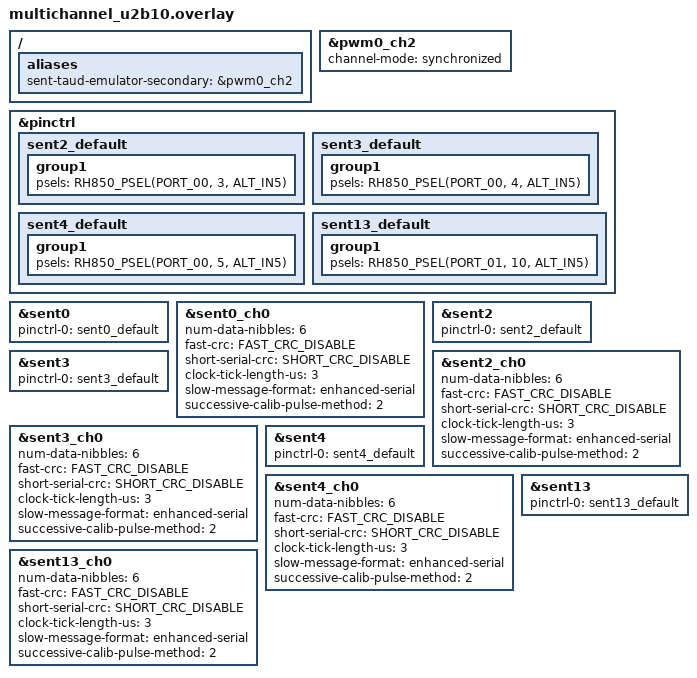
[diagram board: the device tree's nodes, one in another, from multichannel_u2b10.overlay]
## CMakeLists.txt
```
# SPDX-License-Identifier: Apache-2.0
cmake_minimum_required(VERSION 3.20.0)
find_package(Zephyr REQUIRED HINTS $ENV{ZEPHYR_BASE})
project(sent_taud_test_suite)

target_sources(app PRIVATE
  src/main.c
  src/sent_test_common.c
  src/sent_taud_emulator.c
)
target_include_directories(app PRIVATE src)
```

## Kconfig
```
# SPDX-License-Identifier: Apache-2.0

mainmenu "Renesas RH850 SENT driver tests"

source "Kconfig.zephyr"

config SENT_TAUD_TEST_CRC_MODE
	int "CRC mode: 0 disabled, 1 recommended, 2 legacy"
	range 0 2
	default 1

config SENT_TAUD_TEST_PAUSE_MODE
	int "Pause mode: 0 absent, 1 variable, 2 fixed"
	range 0 2
	default 0

config SENT_TAUD_TEST_CALIB_METHOD
	int "Successive calibration method"
	range 1 2
	default 2

config SENT_TAUD_TEST_MULTI_CHANNEL
	bool "Enable two-output multi-channel test"
	default n

config SENT_TAUD_TICK_US
	int "SENT tick length in microseconds"
	default 3
	range 1 100
	help
	  SENT tick duration used to convert raw SENT periods into
	  TAUD counter values.

config SENT_TAUD_TX_TIMEOUT_MS
	int "TAUD raw transmission timeout in milliseconds"
	default 100
	range 1 10000
	help
	  Maximum time to wait for a raw TAUD pulse sequence to finish.
```

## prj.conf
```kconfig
CONFIG_ZTEST=y
CONFIG_SENT=y

CONFIG_LOG=y
CONFIG_LOG_DEFAULT_LEVEL=3

CONFIG_SENT_RENESAS_RH850=y
CONFIG_PWM_RENESAS_RH850=n

CONFIG_MAIN_STACK_SIZE=4096
CONFIG_ISR_STACK_SIZE=4096
CONFIG_HEAP_MEM_POOL_SIZE=4096

CONFIG_ASSERT=y
CONFIG_NO_OPTIMIZATIONS=y

CONFIG_SENT_TAUD_TEST_CRC_MODE=0
CONFIG_SENT_TAUD_TEST_PAUSE_MODE=0
CONFIG_SENT_TAUD_TEST_CALIB_METHOD=2

CONFIG_SENT_TAUD_TICK_US=3
CONFIG_SENT_TAUD_TX_TIMEOUT_MS=100

CONFIG_SENT_RENESAS_RH850_SERIAL_ENHANCED_FRAME=19
```

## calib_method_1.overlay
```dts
/*
 * Copyright (c) 2026 Renesas Electronics Corporation
 * SPDX-License-Identifier: Apache-2.0
 */
&sent1_ch0 {
	successive-calib-pulse-method = <1>;
};
```

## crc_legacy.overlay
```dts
/*
 * Copyright (c) 2026 Renesas Electronics Corporation
 * SPDX-License-Identifier: Apache-2.0
 */
&sent1_ch0 {
	fast-crc = <FAST_CRC_LEGACY_IMPLEMENTATION>;
	short-serial-crc = <SHORT_CRC_LEGACY_IMPLEMENTATION>;
};
```

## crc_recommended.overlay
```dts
/*
 * Copyright (c) 2026 Renesas Electronics Corporation
 * SPDX-License-Identifier: Apache-2.0
 */
&sent1_ch0 {
	fast-crc = <FAST_CRC_RECOMMENDED_IMPLEMENTATION>;
	short-serial-crc = <SHORT_CRC_RECOMMENDED_IMPLEMENTATION>;
};
```

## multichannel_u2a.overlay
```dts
/*
 * Copyright (c) 2026 Renesas Electronics Corporation
 * SPDX-License-Identifier: Apache-2.0
 */

#include <zephyr/dt-bindings/sent/sent.h>

/ {
	aliases {
		sent-taud-emulator-secondary = &pwm0_ch2;
	};
};

/*
 * Enable TAUD0 channel 2 as the second synchronized PWM output.
 * The master channel and primary slave are enabled by the board overlay.
 */
&pwm0_ch2 {
	channel-mode = "synchronized";
	status = "okay";
};

/*
 * Keep these pin configurations test-local instead of exposing them as
 * default board pinctrl nodes.
 */
&pinctrl {
	sent2_default: sent2_default {
		group1 {
			psels = <RH850_PSEL(PORT_04, 13, ALT_IN2)>;
		};
	};

	sent3_default: sent3_default {
		group1 {
			psels = <RH850_PSEL(PORT_04, 12, ALT_IN4)>;
		};
	};

	sent4_default: sent4_default {
		group1 {
			psels = <RH850_PSEL(PORT_06, 13, ALT_IN3)>;
		};
	};
};

/* SENT1 is already enabled by the board overlay. */
&sent0 {
	pinctrl-0 = <&sent0_default>;
	pinctrl-names = "default";
	status = "okay";
};

&sent0_ch0 {
	num-data-nibbles = <6>;
	fast-crc = <FAST_CRC_DISABLE>;
	short-serial-crc = <SHORT_CRC_DISABLE>;
	clock-tick-length-us = <3>;
	slow-message-format = "enhanced-serial";
	successive-calib-pulse-method = <2>;
	status = "okay";
};

&sent2 {
	pinctrl-0 = <&sent2_default>;
	pinctrl-names = "default";
	status = "okay";
};

&sent2_ch0 {
	num-data-nibbles = <6>;
	fast-crc = <FAST_CRC_DISABLE>;
	short-serial-crc = <SHORT_CRC_DISABLE>;
	clock-tick-length-us = <3>;
	slow-message-format = "enhanced-serial";
	successive-calib-pulse-method = <2>;
	status = "okay";
};

&sent3 {
	pinctrl-0 = <&sent3_default>;
	pinctrl-names = "default";
	status = "okay";
};

&sent3_ch0 {
	num-data-nibbles = <6>;
	fast-crc = <FAST_CRC_DISABLE>;
	short-serial-crc = <SHORT_CRC_DISABLE>;
	clock-tick-length-us = <3>;
	slow-message-format = "enhanced-serial";
	successive-calib-pulse-method = <2>;
	status = "okay";
};

&sent4 {
	pinctrl-0 = <&sent4_default>;
	pinctrl-names = "default";
	status = "okay";
};

&sent4_ch0 {
	num-data-nibbles = <6>;
	fast-crc = <FAST_CRC_DISABLE>;
	short-serial-crc = <SHORT_CRC_DISABLE>;
	clock-tick-length-us = <3>;
	slow-message-format = "enhanced-serial";
	successive-calib-pulse-method = <2>;
	status = "okay";
};

#undef SENT_CHANNEL_CONFIG
```

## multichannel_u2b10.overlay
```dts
/*
 * Copyright (c) 2026 Renesas Electronics Corporation
 * SPDX-License-Identifier: Apache-2.0
 *
 * U2B10 multi-channel SENT test overlay.
 *
 * SENT13 is U2B10-specific and is included in main.c only when node label
 * sent13 exists and has status = "okay".
 */

#include <zephyr/dt-bindings/sent/sent.h>

/ {
	aliases {
		sent-taud-emulator-secondary = &pwm0_ch2;
	};
};

/*
 * Enable TAUD0 channel 2 as the second synchronized PWM output.
 * The master channel and primary slave are enabled by the board overlay.
 */
&pwm0_ch2 {
	channel-mode = "synchronized";
	status = "okay";
};

&pinctrl {
	sent2_default: sent2_default {
		group1 {
			psels = <RH850_PSEL(PORT_00, 3, ALT_IN5)>;
		};
	};

	sent3_default: sent3_default {
		group1 {
			psels = <RH850_PSEL(PORT_00, 4, ALT_IN5)>;
		};
	};

	sent4_default: sent4_default {
		group1 {
			psels = <RH850_PSEL(PORT_00, 5, ALT_IN5)>;
		};
	};

	sent13_default: sent13_default {
		group1 {
			psels = <RH850_PSEL(PORT_01, 10, ALT_IN5)>;
		};
	};
};

/* SENT1 is already enabled by the board overlay. */
&sent0 {
	pinctrl-0 = <&sent0_default>;
	pinctrl-names = "default";
	status = "okay";
};

&sent0_ch0 {
	num-data-nibbles = <6>;
	fast-crc = <FAST_CRC_DISABLE>;
	short-serial-crc = <SHORT_CRC_DISABLE>;
	clock-tick-length-us = <3>;
	slow-message-format = "enhanced-serial";
	successive-calib-pulse-method = <2>;
	status = "okay";
};

&sent2 {
	pinctrl-0 = <&sent2_default>;
	pinctrl-names = "default";
	status = "okay";
};

&sent2_ch0 {
	num-data-nibbles = <6>;
	fast-crc = <FAST_CRC_DISABLE>;
	short-serial-crc = <SHORT_CRC_DISABLE>;
	clock-tick-length-us = <3>;
	slow-message-format = "enhanced-serial";
	successive-calib-pulse-method = <2>;
	status = "okay";
};

&sent3 {
	pinctrl-0 = <&sent3_default>;
	pinctrl-names = "default";
	status = "okay";
};

&sent3_ch0 {
	num-data-nibbles = <6>;
	fast-crc = <FAST_CRC_DISABLE>;
	short-serial-crc = <SHORT_CRC_DISABLE>;
	clock-tick-length-us = <3>;
	slow-message-format = "enhanced-serial";
	successive-calib-pulse-method = <2>;
	status = "okay";
};

&sent4 {
	pinctrl-0 = <&sent4_default>;
	pinctrl-names = "default";
	status = "okay";
};

&sent4_ch0 {
	num-data-nibbles = <6>;
	fast-crc = <FAST_CRC_DISABLE>;
	short-serial-crc = <SHORT_CRC_DISABLE>;
	clock-tick-length-us = <3>;
	slow-message-format = "enhanced-serial";
	successive-calib-pulse-method = <2>;
	status = "okay";
};

&sent13 {
	pinctrl-0 = <&sent13_default>;
	pinctrl-names = "default";
	status = "okay";
};

&sent13_ch0 {
	num-data-nibbles = <6>;
	fast-crc = <FAST_CRC_DISABLE>;
	short-serial-crc = <SHORT_CRC_DISABLE>;
	clock-tick-length-us = <3>;
	slow-message-format = "enhanced-serial";
	successive-calib-pulse-method = <2>;
	status = "okay";
};

#undef SENT_CHANNEL_CONFIG
```

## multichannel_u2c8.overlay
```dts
/*
 * Copyright (c) 2026 Renesas Electronics Corporation
 * SPDX-License-Identifier: Apache-2.0
 */

#include <zephyr/dt-bindings/sent/sent.h>

/ {
	aliases {
		sent-taud-emulator-secondary = &pwm0_ch2;
	};
};

/*
 * Enable TAUD0 channel 2 as the second synchronized PWM output.
 * The master channel and primary slave are enabled by the board overlay.
 */
&pwm0_ch2 {
	channel-mode = "synchronized";
	status = "okay";
};

&pinctrl {
	sent2_default: sent2_default {
		group1 {
			psels = <RH850_PSEL(PORT_02, 9, ALT_IN5)>;
		};
	};

	sent3_default: sent3_default {
		group1 {
			psels = <RH850_PSEL(PORT_04, 13, ALT_IN5)>;
		};
	};

	sent4_default: sent4_default {
		group1 {
			psels = <RH850_PSEL(PORT_04, 15, ALT_IN6)>;
		};
	};
};

/* SENT1 is already enabled by the board overlay. */
&sent0 {
	pinctrl-0 = <&sent0_default>;
	pinctrl-names = "default";
	status = "okay";
};

&sent0_ch0 {
	num-data-nibbles = <6>;
	fast-crc = <FAST_CRC_DISABLE>;
	short-serial-crc = <SHORT_CRC_DISABLE>;
	clock-tick-length-us = <3>;
	slow-message-format = "enhanced-serial";
	successive-calib-pulse-method = <2>;
	status = "okay";
};

&sent2 {
	pinctrl-0 = <&sent2_default>;
	pinctrl-names = "default";
	status = "okay";
};

&sent2_ch0 {
	num-data-nibbles = <6>;
	fast-crc = <FAST_CRC_DISABLE>;
	short-serial-crc = <SHORT_CRC_DISABLE>;
	clock-tick-length-us = <3>;
	slow-message-format = "enhanced-serial";
	successive-calib-pulse-method = <2>;
	status = "okay";
};

&sent3 {
	pinctrl-0 = <&sent3_default>;
	pinctrl-names = "default";
	status = "okay";
};

&sent3_ch0 {
	num-data-nibbles = <6>;
	fast-crc = <FAST_CRC_DISABLE>;
	short-serial-crc = <SHORT_CRC_DISABLE>;
	clock-tick-length-us = <3>;
	slow-message-format = "enhanced-serial";
	successive-calib-pulse-method = <2>;
	status = "okay";
};

&sent4 {
	pinctrl-0 = <&sent4_default>;
	pinctrl-names = "default";
	status = "okay";
};

&sent4_ch0 {
	num-data-nibbles = <6>;
	fast-crc = <FAST_CRC_DISABLE>;
	short-serial-crc = <SHORT_CRC_DISABLE>;
	clock-tick-length-us = <3>;
	slow-message-format = "enhanced-serial";
	successive-calib-pulse-method = <2>;
	status = "okay";
};


#undef SENT_CHANNEL_CONFIG
```

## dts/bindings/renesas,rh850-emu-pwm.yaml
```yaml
# Copyright (c) 2026 Renesas Electronics Corporation
# SPDX-License-Identifier: Apache-2.0

description: |
  Renesas RH850 TAUD-Emulator PWM driver (master/slave).

  Used for both master and slave nodes:
  - Master node: channel-type = "master" (timing source, no PWM output)
  - Slave node:  channel-type = "slave"  (PWM output, requires a Master Channel phandle)

compatible: "renesas,rh850-emu-pwm"

include: [base.yaml, pinctrl-device.yaml]

properties:
  reg:
    required: true

  unit:
    type: int
    required: true
    description: |
      TAUD Unit number (e.g. 0 for TAUD0).
      The valid range depends on the available hardware.

  channel:
    type: int
    required: true
    description: TAUD Channel number within the Unit (range from 0 to 15).

  channel-type:
    type: string
    required: true
    enum:
      - "master"
      - "slave"
    description: |
      Type of TAUD channel:

      "master" - Timing source used to set the PWM period/frequency.
                 It does not output the PWM signal directly.

      "slave"  - PWM output channel used to set the duty cycle.
                 It must reference a Master Channel by phandle.

  master:
    type: phandle
    description: Phandle to the master TAUD channel node.
      Required for slave nodes (channel-type = "slave").
      Must not be present for master nodes.

  interrupts:
    required: true

  "#pwm-cells":
    type: int
    const: 3

pwm-cells:
  - channel
  - period
  - flags
```

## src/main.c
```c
/*
 * Copyright (c) 2026 Renesas Electronics Corporation
 * SPDX-License-Identifier: Apache-2.0
 */

#include <stdbool.h>
#include <stddef.h>
#include <stdint.h>

#include <zephyr/device.h>
#include <zephyr/devicetree.h>
#include <zephyr/kernel.h>
#include <zephyr/sys/util.h>
#include <zephyr/ztest.h>

#include "sent_taud_emulator.h"
#include "sent_test_common.h"
#include "sent_test_vectors.h"

#define SENT0_NODE DT_ALIAS(sent0)

#if !DT_NODE_EXISTS(SENT0_NODE)
#error "sent0 Devicetree alias is not defined"
#endif

#if !DT_NODE_HAS_STATUS_OKAY(SENT0_NODE)
#error "sent0 Devicetree node is not enabled"
#endif

#define TEST_RX_TIMEOUT K_MSEC(250U)

static const struct device *const sent0 = DEVICE_DT_GET(SENT0_NODE);
static struct sent_test_rx_context rx0;
static bool sent0_started;

#if IS_ENABLED(CONFIG_SENT_TAUD_TEST_MULTI_CHANNEL)

/*
 * The multichannel overlay enables all required physical RSENT instances.
 * Do not use aliases here because the base overlay may map alias sent0 to a
 * different physical node for the normal single-channel tests.
 */
#define SENT_PHYS0_NODE  DT_NODELABEL(sent0)
#define SENT_PHYS1_NODE  DT_NODELABEL(sent1)
#define SENT_PHYS2_NODE  DT_NODELABEL(sent2)
#define SENT_PHYS3_NODE  DT_NODELABEL(sent3)
#define SENT_PHYS4_NODE  DT_NODELABEL(sent4)
#define SENT_PHYS13_NODE DT_NODELABEL(sent13)

#if DT_NODE_EXISTS(SENT_PHYS13_NODE) && DT_NODE_HAS_STATUS_OKAY(SENT_PHYS13_NODE)
#define MULTI_HAS_SENT13 1
#else
#define MULTI_HAS_SENT13 0
#endif

BUILD_ASSERT(DT_NODE_HAS_STATUS_OKAY(SENT_PHYS0_NODE),
			 "multichannel requires physical SENT0");
BUILD_ASSERT(DT_NODE_HAS_STATUS_OKAY(SENT_PHYS1_NODE),
			 "multichannel requires physical SENT1");
BUILD_ASSERT(DT_NODE_HAS_STATUS_OKAY(SENT_PHYS2_NODE),
			 "multichannel requires physical SENT2");
BUILD_ASSERT(DT_NODE_HAS_STATUS_OKAY(SENT_PHYS3_NODE),
			 "multichannel requires physical SENT3");
BUILD_ASSERT(DT_NODE_HAS_STATUS_OKAY(SENT_PHYS4_NODE),
			 "multichannel requires physical SENT4");

#if MULTI_HAS_SENT13
BUILD_ASSERT(DT_NODE_HAS_STATUS_OKAY(SENT_PHYS13_NODE),
			 "multichannel SENT13 node must be enabled");
#define MULTI_SENT_COUNT 6U
#else
#define MULTI_SENT_COUNT 5U
#endif

static const struct device *const multi_sent_devs[MULTI_SENT_COUNT] = {
	DEVICE_DT_GET(SENT_PHYS0_NODE),
	DEVICE_DT_GET(SENT_PHYS1_NODE),
	DEVICE_DT_GET(SENT_PHYS2_NODE),
	DEVICE_DT_GET(SENT_PHYS3_NODE),
	DEVICE_DT_GET(SENT_PHYS4_NODE),
#if MULTI_HAS_SENT13
	DEVICE_DT_GET(SENT_PHYS13_NODE),
#endif
};

static struct sent_test_rx_context multi_rx[MULTI_SENT_COUNT];
static bool multi_started[MULTI_SENT_COUNT];

static uint32_t multi_sent_hw_channel(size_t index)
{
	static const uint32_t hw_channels[] = {
		0U, 1U, 2U, 3U, 4U,
#if MULTI_HAS_SENT13
		13U,
#endif
	};

	return hw_channels[index];
}

#endif /* CONFIG_SENT_TAUD_TEST_MULTI_CHANNEL */

static void send_raw(const uint32_t *periods, size_t period_count)
{
	int ret = sent_taud_emulator_send_raw(periods, period_count);

	zassert_equal(ret, 0, "TAUD raw transmission failed: %d", ret);
}

static void start_fast(uint32_t frame_count)
{
	int ret = sent_test_start_fast(sent0, &rx0, frame_count);

	zassert_equal(ret, 0, "Failed to start Fast Channel reception: %d", ret);
	sent0_started = true;
}

static void wait_fast(void)
{
	int ret = k_sem_take(&rx0.done, TEST_RX_TIMEOUT);

	zassert_equal(ret, 0, "Timed out waiting for Fast Channel callback");
}

static void assert_zero_data_frame(const struct sent_frame *frame)
{
	zassert_equal(frame->type, SENT_FAST_FRAME);
	zassert_equal(frame->fast.data_nibbles[0], 0U);
	zassert_equal(frame->fast.data_nibbles[1], 0U);
	zassert_equal(frame->fast.data_nibbles[2], 0U);
	zassert_equal(frame->fast.data_nibbles[3], 0U);
	zassert_equal(frame->fast.data_nibbles[4], 0U);
	zassert_equal(frame->fast.data_nibbles[5], 0U);
}

static void assert_crc_payload_frame(const struct sent_frame *frame)
{
	zassert_equal(frame->type, SENT_FAST_FRAME);
	zassert_equal(frame->fast.data_nibbles[0], 0x1U);
	zassert_equal(frame->fast.data_nibbles[1], 0x2U);
	zassert_equal(frame->fast.data_nibbles[2], 0x3U);
	zassert_equal(frame->fast.data_nibbles[3], 0x4U);
	zassert_equal(frame->fast.data_nibbles[4], 0x5U);
	zassert_equal(frame->fast.data_nibbles[5], 0x6U);
}

static void *suite_setup(void)
{
	int ret;

	zassert_true(device_is_ready(sent0), "sent0 is not ready");

	ret = sent_test_rx_context_init(&rx0);
	zassert_equal(ret, 0, "Failed to initialize RX context: %d", ret);

#if IS_ENABLED(CONFIG_SENT_TAUD_TEST_MULTI_CHANNEL)
	for (size_t i = 0U; i < MULTI_SENT_COUNT; i++) {
		zassert_true(device_is_ready(multi_sent_devs[i]),
					 "Physical SENT%u is not ready", multi_sent_hw_channel(i));

		ret = sent_test_rx_context_init(&multi_rx[i]);
		zassert_equal(ret, 0,
					  "Failed to initialize physical SENT%u RX context: %d",
					  multi_sent_hw_channel(i), ret);
	}
#endif

	ret = sent_taud_emulator_open();
	zassert_equal(ret, 0, "Failed to open TAUD emulator: %d", ret);

	return NULL;
}

static void before(void *fixture)
{
	ARG_UNUSED(fixture);

	sent0_started = false;
	sent_test_rx_context_reset(&rx0);

#if IS_ENABLED(CONFIG_SENT_TAUD_TEST_MULTI_CHANNEL)
	for (size_t i = 0U; i < MULTI_SENT_COUNT; i++) {
		multi_started[i] = false;
		sent_test_rx_context_reset(&multi_rx[i]);
	}
#endif
}

static void after(void *fixture)
{
	int ret;

	ARG_UNUSED(fixture);

	if (sent0_started) {
		ret = sent_test_stop(sent0);
		zassert_equal(ret, 0, "Failed to stop SENT receiver: %d", ret);
		sent0_started = false;
	}

#if IS_ENABLED(CONFIG_SENT_TAUD_TEST_MULTI_CHANNEL)
	for (size_t i = 0U; i < MULTI_SENT_COUNT; i++) {
		if (!multi_started[i]) {
			continue;
		}

		ret = sent_test_stop(multi_sent_devs[i]);
		zassert_equal(ret, 0, "Failed to stop physical SENT%u: %d",
					  multi_sent_hw_channel(i), ret);
		multi_started[i] = false;
	}
#endif
}

static void suite_teardown(void *fixture)
{
	int ret;

	ARG_UNUSED(fixture);

	ret = sent_taud_emulator_close();
	zassert_equal(ret, 0, "Failed to close TAUD emulator: %d", ret);
}

ZTEST(sent_rh850_taud_raw, test_reference_vector_19_frames)
{
#if IS_ENABLED(CONFIG_SENT_TAUD_TEST_MULTI_CHANNEL) || \
	(CONFIG_SENT_TAUD_TEST_PAUSE_MODE != 0) || \
	(CONFIG_SENT_TAUD_TEST_CRC_MODE != 0)
	ztest_test_skip();
#else
	start_fast(FSP_REFERENCE_FRAME_COUNT);
	send_raw(fsp_enhanced_serial_format_0_pulses,
			 ARRAY_SIZE(fsp_enhanced_serial_format_0_pulses));
	wait_fast();

	zassert_equal(rx0.callback_count, 1U);
	zassert_equal(rx0.frame_total, FSP_REFERENCE_FRAME_COUNT);
	assert_zero_data_frame(&rx0.frames[0]);
	zassert_equal(rx0.frames[2].fast.data_nibbles[5], 0x1U);
	zassert_equal(rx0.frames[18].fast.data_nibbles[4], 0x1U);
	zassert_equal(rx0.frames[18].fast.data_nibbles[5], 0x1U);
#endif
}

ZTEST(sent_rh850_taud_raw, test_known_good_single_frame)
{
#if IS_ENABLED(CONFIG_SENT_TAUD_TEST_MULTI_CHANNEL) || \
	(CONFIG_SENT_TAUD_TEST_PAUSE_MODE != 0) || \
	(CONFIG_SENT_TAUD_TEST_CRC_MODE != 0)
	ztest_test_skip();
#else
	start_fast(1U);
	send_raw(known_good_single_frame, ARRAY_SIZE(known_good_single_frame));
	wait_fast();

	zassert_equal(rx0.callback_count, 1U);
	zassert_equal(rx0.frame_total, 1U);
	assert_zero_data_frame(&rx0.frames[0]);
#endif
}

ZTEST(sent_rh850_taud_raw, test_calibration_error_recovery)
{
#if IS_ENABLED(CONFIG_SENT_TAUD_TEST_MULTI_CHANNEL) || \
	(CONFIG_SENT_TAUD_TEST_PAUSE_MODE != 0) || \
	(CONFIG_SENT_TAUD_TEST_CRC_MODE != 0)
	ztest_test_skip();
#else
	start_fast(1U);
	send_raw(bad_calibration_single_frame,
			 ARRAY_SIZE(bad_calibration_single_frame));
	k_msleep(20U);
	zassert_equal(rx0.callback_count, 0U,
				  "Invalid calibration unexpectedly produced a Fast callback");

	send_raw(known_good_single_frame, ARRAY_SIZE(known_good_single_frame));
	wait_fast();
	zassert_equal(rx0.callback_count, 1U);
	zassert_equal(rx0.frame_total, 1U);
	assert_zero_data_frame(&rx0.frames[0]);
#endif
}

ZTEST(sent_rh850_taud_raw, test_crc_valid_raw)
{
#if IS_ENABLED(CONFIG_SENT_TAUD_TEST_MULTI_CHANNEL) || \
	(CONFIG_SENT_TAUD_TEST_PAUSE_MODE != 0)
	ztest_test_skip();
#elif CONFIG_SENT_TAUD_TEST_CRC_MODE == 1
	start_fast(1U);
	send_raw(recommended_crc_single_frame,
			 ARRAY_SIZE(recommended_crc_single_frame));
	wait_fast();
	zassert_equal(rx0.callback_count, 1U);
	zassert_equal(rx0.frame_total, 1U);
	assert_crc_payload_frame(&rx0.frames[0]);
#elif CONFIG_SENT_TAUD_TEST_CRC_MODE == 2
	start_fast(1U);
	send_raw(legacy_crc_single_frame, ARRAY_SIZE(legacy_crc_single_frame));
	wait_fast();
	zassert_equal(rx0.callback_count, 1U);
	zassert_equal(rx0.frame_total, 1U);
	assert_crc_payload_frame(&rx0.frames[0]);
#else
	ztest_test_skip();
#endif
}

ZTEST(sent_rh850_taud_raw, test_crc_error_recovery_raw)
{
#if IS_ENABLED(CONFIG_SENT_TAUD_TEST_MULTI_CHANNEL) || \
	(CONFIG_SENT_TAUD_TEST_PAUSE_MODE != 0) || \
	(CONFIG_SENT_TAUD_TEST_CRC_MODE == 0)
	ztest_test_skip();
#elif CONFIG_SENT_TAUD_TEST_CRC_MODE == 1
	start_fast(1U);
	send_raw(bad_recommended_crc_single_frame,
			 ARRAY_SIZE(bad_recommended_crc_single_frame));
	k_msleep(20U);
	zassert_equal(rx0.callback_count, 0U);

	send_raw(recommended_crc_single_frame,
			 ARRAY_SIZE(recommended_crc_single_frame));
	wait_fast();
	zassert_equal(rx0.callback_count, 1U);
	zassert_equal(rx0.frame_total, 1U);
	assert_crc_payload_frame(&rx0.frames[0]);
#else
	start_fast(1U);
	send_raw(bad_legacy_crc_single_frame,
			 ARRAY_SIZE(bad_legacy_crc_single_frame));
	k_msleep(20U);
	zassert_equal(rx0.callback_count, 0U);

	send_raw(legacy_crc_single_frame, ARRAY_SIZE(legacy_crc_single_frame));
	wait_fast();
	zassert_equal(rx0.callback_count, 1U);
	zassert_equal(rx0.frame_total, 1U);
	assert_crc_payload_frame(&rx0.frames[0]);
#endif
}

ZTEST(sent_rh850_taud_raw, test_pause_pulse_raw)
{
#if IS_ENABLED(CONFIG_SENT_TAUD_TEST_MULTI_CHANNEL) || \
	(CONFIG_SENT_TAUD_TEST_PAUSE_MODE == 0)
	ztest_test_skip();
#elif CONFIG_SENT_TAUD_TEST_PAUSE_MODE == 1
	start_fast(4U);
	send_raw(variable_pause_frames, ARRAY_SIZE(variable_pause_frames));
	wait_fast();

	zassert_equal(rx0.callback_count, 1U);
	zassert_equal(rx0.frame_total, 4U);
	assert_zero_data_frame(&rx0.frames[0]);
	assert_zero_data_frame(&rx0.frames[1]);
	assert_zero_data_frame(&rx0.frames[2]);
	assert_zero_data_frame(&rx0.frames[3]);
#else
	start_fast(4U);
	send_raw(fixed_pause_frames, ARRAY_SIZE(fixed_pause_frames));
	wait_fast();

	zassert_equal(rx0.callback_count, 1U);
	zassert_equal(rx0.frame_total, 4U);
	assert_zero_data_frame(&rx0.frames[0]);
	assert_zero_data_frame(&rx0.frames[1]);
	assert_zero_data_frame(&rx0.frames[2]);
	assert_zero_data_frame(&rx0.frames[3]);
#endif
}

/*
 * Keep this ZTEST visible in every configuration so Twister receives an
 * explicit SKIP instead of retaining a None status in non-multichannel runs.
 */
ZTEST(sent_rh850_taud_raw, test_multichannel_same_stream_all_receivers)
{
#if !IS_ENABLED(CONFIG_SENT_TAUD_TEST_MULTI_CHANNEL)
	ztest_test_skip();
#else
	int ret;

	/*
	 * Arm every physical receiver first. sent_test_start_fast() registers
	 * sent_test_fast_cb() with &multi_rx[i] as user_data and starts listening.
	 */
	for (size_t i = 0U; i < MULTI_SENT_COUNT; i++) {
		ret = sent_test_start_fast(multi_sent_devs[i], &multi_rx[i],
								   FSP_REFERENCE_FRAME_COUNT);
		zassert_equal(ret, 0,
					  "Failed to start physical SENT%u: %d",
					  multi_sent_hw_channel(i), ret);
		multi_started[i] = true;
	}

	/* One TAUD transmission is observed by every wired physical receiver. */
	send_raw(fsp_enhanced_serial_format_0_pulses,
			 ARRAY_SIZE(fsp_enhanced_serial_format_0_pulses));

	/* The callback gives multi_rx[i].done through its user_data context. */
	for (size_t i = 0U; i < MULTI_SENT_COUNT; i++) {
		ret = k_sem_take(&multi_rx[i].done, TEST_RX_TIMEOUT);

		if (ret != 0) {
			printk("SENT timeout: index=%u physical=%u ret=%d "
				   "callback_count=%u frame_total=%u\n",
				   (unsigned int)i,
				   multi_sent_hw_channel(i),
				   ret,
				   multi_rx[i].callback_count,
				   multi_rx[i].frame_total);
		}

		zassert_equal(ret, 0,
					  "Timed out waiting for physical SENT%u callback: ret=%d",
					  multi_sent_hw_channel(i), ret);
	}

	for (size_t i = 0U; i < MULTI_SENT_COUNT; i++) {
		zassert_equal(multi_rx[i].callback_count, 1U,
				"Unexpected physical SENT%u callback count: %u",
				multi_sent_hw_channel(i),
				multi_rx[i].callback_count);

		zassert_equal(multi_rx[i].frame_total,
				FSP_REFERENCE_FRAME_COUNT,
				"Unexpected physical SENT%u frame total: %u",
				multi_sent_hw_channel(i),
				multi_rx[i].frame_total);

		assert_zero_data_frame(&multi_rx[i].frames[0]);

		TC_PRINT("SENT%u:\n", multi_sent_hw_channel(i));

		for (size_t frame = 0U; frame < FSP_REFERENCE_FRAME_COUNT; frame++) {
			const struct sent_frame *f = &multi_rx[i].frames[frame];

			TC_PRINT(
				"frame %02u: %X %X %X %X %X %X "
				"(exp4=%X exp5=%X)\n",
				frame,
				f->fast.data_nibbles[0],
				f->fast.data_nibbles[1],
				f->fast.data_nibbles[2],
				f->fast.data_nibbles[3],
				f->fast.data_nibbles[4],
				f->fast.data_nibbles[5],
				expected_nibble4[frame],
				expected_final_nibble[frame]);

			zassert_equal(
				f->fast.data_nibbles[4],
				expected_nibble4[frame],
				"Physical SENT%u frame %u nibble4 mismatch",
				multi_sent_hw_channel(i),
				frame);

			zassert_equal(
				f->fast.data_nibbles[5],
				expected_final_nibble[frame],
				"Physical SENT%u frame %u nibble5 mismatch",
				multi_sent_hw_channel(i),
				frame);
		}
	}
#endif
}

ZTEST_SUITE(sent_rh850_taud_raw,
			NULL,
			suite_setup,
			before,
			after,
			suite_teardown);
```

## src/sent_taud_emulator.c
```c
/*
 * Copyright (c) 2026 Renesas Electronics Corporation
 * SPDX-License-Identifier: Apache-2.0
 */
#include "sent_taud_emulator.h"

#include <errno.h>
#include <stdbool.h>
#include <stddef.h>
#include <stdint.h>

#include <zephyr/devicetree.h>
#include <zephyr/drivers/clock_control.h>
#include <zephyr/drivers/pinctrl.h>
#include <zephyr/irq.h>
#include <zephyr/kernel.h>
#include <zephyr/logging/log.h>
#include <zephyr/sys/util.h>

#include "bsp_api.h"

LOG_MODULE_REGISTER(
	sent_taud_emulator,
	CONFIG_LOG_DEFAULT_LEVEL);

/*
 * The sent-taud-emulator alias points directly to the TAUD slave
 * channel used as the SENT output.
 *
 * Example:
 *
 * / {
 *     aliases {
 *         sent-taud-emulator = &pwm0_slave;
 *     };
 * };
 */
#define SENT_TAUD_EMULATOR_NODE \
	DT_ALIAS(sent_taud_emulator)

#if !DT_NODE_EXISTS(SENT_TAUD_EMULATOR_NODE)
#error "sent-taud-emulator Devicetree alias is not defined"
#endif

#if !DT_NODE_HAS_STATUS_OKAY(SENT_TAUD_EMULATOR_NODE)
#error "SENT TAUD emulator Devicetree node is not enabled"
#endif

/*
 * Optional second slave output.
 *
 * When sent-taud-emulator-secondary is present and enabled, both slaves
 * follow the same master period stream. Only the primary slave interrupt
 * advances active_pulse_index; the secondary slave is output-only.
 */
#define SENT_TAUD_EMULATOR_SECONDARY_NODE \
	DT_ALIAS(sent_taud_emulator_secondary)

#if DT_NODE_EXISTS(SENT_TAUD_EMULATOR_SECONDARY_NODE) && \
	DT_NODE_HAS_STATUS_OKAY(SENT_TAUD_EMULATOR_SECONDARY_NODE)
#define EMU_HAS_SECONDARY_SLAVE 1
#else
#define EMU_HAS_SECONDARY_SLAVE 0
#endif

/*
 * The alias points to a synchronized output child of the standard TAUD PWM
 * binding. Its parent is the primary TAUD channel used as the master.
 */
#define EMU_MASTER_NODE \
	DT_PARENT(SENT_TAUD_EMULATOR_NODE)

#if !DT_NODE_HAS_STATUS_OKAY(EMU_MASTER_NODE)
#error "SENT TAUD emulator primary channel is not enabled"
#endif

#if EMU_HAS_SECONDARY_SLAVE
#define EMU_SECONDARY_MASTER_NODE \
	DT_PARENT(SENT_TAUD_EMULATOR_SECONDARY_NODE)
#endif

/*
 * TAUD instance and channel configuration.
 */
#define EMU_TAUD_UNIT \
	DT_PROP(EMU_MASTER_NODE, unit)

#define EMU_MASTER_CH \
	DT_PROP(EMU_MASTER_NODE, channel)

#define EMU_SLAVE_CH \
	DT_REG_ADDR(SENT_TAUD_EMULATOR_NODE)

#if EMU_HAS_SECONDARY_SLAVE
#define EMU_SECONDARY_SLAVE_CH \
	DT_REG_ADDR(SENT_TAUD_EMULATOR_SECONDARY_NODE)
#endif

/*
 * All synchronized children use the clock owned by the primary node.
 */
#define EMU_CLOCK_CTLR \
	DT_CLOCKS_CTLR(EMU_MASTER_NODE)

#define EMU_CLOCK_ID \
	DT_CLOCKS_CELL(EMU_MASTER_NODE, clk_id)

static const struct device *const emulator_clock_dev =
	DEVICE_DT_GET(EMU_CLOCK_CTLR);

/*
 * TAUD interrupt configuration.
 */
#define EMU_MASTER_IRQ \
	DT_IRQN(EMU_MASTER_NODE)

#define EMU_SLAVE_IRQ \
	DT_IRQN(SENT_TAUD_EMULATOR_NODE)

#define EMU_MASTER_IRQ_PRIORITY \
	DT_IRQ(EMU_MASTER_NODE, priority)

#define EMU_SLAVE_IRQ_PRIORITY \
	DT_IRQ(SENT_TAUD_EMULATOR_NODE, priority)

BUILD_ASSERT(
	EMU_TAUD_UNIT == 0U,
	"Current SENT emulator supports TAUD0 only");

BUILD_ASSERT(
	EMU_MASTER_CH == 0U,
	"Current SENT emulator expects TAUD0 channel 0 as primary");

#if EMU_HAS_SECONDARY_SLAVE
BUILD_ASSERT(
	DT_SAME_NODE(EMU_MASTER_NODE, EMU_SECONDARY_MASTER_NODE),
	"Primary and secondary slaves must use the same TAUD master");
BUILD_ASSERT(
	EMU_SLAVE_CH != EMU_SECONDARY_SLAVE_CH,
	"Primary and secondary TAUD slave channels must differ");
#define EMU_SECONDARY_CH_MASK BIT(EMU_SECONDARY_SLAVE_CH)
#else
#define EMU_SECONDARY_CH_MASK 0U
#endif

#define EMU_CH_MASK \
	(BIT(EMU_MASTER_CH) | BIT(EMU_SLAVE_CH) | EMU_SECONDARY_CH_MASK)

/*
 * The standard binding routes all synchronized output pins through the
 * primary TAUD node.
 */
PINCTRL_DT_DEFINE(EMU_MASTER_NODE);

static const struct pinctrl_dev_config *const emulator_pinctrl =
	PINCTRL_DT_DEV_CONFIG_GET(
		EMU_MASTER_NODE);

/*
 * The current TAUD configuration produces a 10 MHz counter clock.
 *
 * Therefore:
 *
 *     1 us = 10 TAUD counts
 */
#define EMU_COUNTS_PER_US 10U

/*
 * Fixed low-level pulse width used by the TAUD slave output channel.
 *
 * This matches the original FSP test emulator:
 *
 *     slave CDR = 5 SENT ticks
 */
#define EMU_LOW_TICKS 5U

K_SEM_DEFINE(tx_done, 0, 1);

/*
 * Active raw pulse stream.
 *
 * The caller must keep the source array valid until
 * sent_taud_emulator_send_raw() returns.
 */
static const uint32_t *active_pulses;
static size_t active_pulse_count;
static volatile size_t active_pulse_index;
static bool emulator_opened;

/*
 * Debug information retained after a timeout.
 *
 * These variables can be inspected directly from the debugger.
 */
volatile size_t sent_taud_debug_pulse_index;
volatile size_t sent_taud_debug_pulse_count;
volatile uint32_t sent_taud_debug_current_ticks;

/*
 * Convert a raw SENT tick count into the value expected by TAUDnCDR.
 *
 * TAUD counts from the configured value down to zero, therefore the
 * programmed value is:
 *
 *     number_of_counts - 1
 */
static uint16_t sent_taud_ticks_to_counter(uint32_t ticks)
{
	uint64_t counter_value;

	__ASSERT_NO_MSG(ticks > 0U);

	counter_value =
		(uint64_t)ticks *
		(uint64_t)CONFIG_SENT_TAUD_TICK_US *
		(uint64_t)EMU_COUNTS_PER_US;

	__ASSERT_NO_MSG(
		counter_value <=
		((uint64_t)UINT16_MAX + 1U));

	return (uint16_t)(counter_value - 1U);
}

/*
 * The master interrupt is used internally as the slave-channel trigger.
 *
 * The interrupt status must still be acknowledged, but the next pulse is
 * loaded from the slave interrupt.
 */
static void sent_taud_master_isr(const void *arg)
{
	ARG_UNUSED(arg);

	R_BSP_IrqStatusClear(
		(IRQn_Type)EMU_MASTER_IRQ);
}

/*
 * Load the next raw pulse period.
 *
 * The initial period is loaded by sent_taud_emulator_send_raw(). Each
 * subsequent slave interrupt advances to the next array entry.
 */
static void sent_taud_slave_isr(const void *arg)
{
	ARG_UNUSED(arg);

	R_BSP_IrqStatusClear(
		(IRQn_Type)EMU_SLAVE_IRQ);

	sent_taud_debug_pulse_index =
		active_pulse_index;

	sent_taud_debug_pulse_count =
		active_pulse_count;

	/*
	 * Stop after the final pulse period has completed.
	 *
	 * Unlike the FSP test emulator, no SENT_EMU_END_NIBBLE_MARK is
	 * required. The supplied array length determines the end.
	 */
	if ((active_pulses == NULL) ||
	    (active_pulse_index >= active_pulse_count)) {
		R_TAUD0->TAUDnTT =
			EMU_CH_MASK;

		k_sem_give(&tx_done);

		return;
	}

	sent_taud_debug_current_ticks =
		active_pulses[active_pulse_index];

	R_TAUD0
		->TAUDnCDR[EMU_MASTER_CH]
		.TAUDnCDR =
		sent_taud_ticks_to_counter(
			active_pulses[active_pulse_index]);

	active_pulse_index++;
}

static int sent_taud_emulator_clock_init(void)
{
	int ret;

	if (!device_is_ready(emulator_clock_dev)) {
		LOG_ERR("TAUD clock device is not ready");
		return -ENODEV;
	}

	ret = clock_control_on(
		emulator_clock_dev,
		(clock_control_subsys_t)(uintptr_t)EMU_CLOCK_ID);
	if (ret < 0) {
		LOG_ERR("Failed to enable TAUD clock: %d", ret);
		return ret;
	}

	return 0;
}

int sent_taud_emulator_open(void)
{
	int ret;

	if (emulator_opened) {
		return -EALREADY;
	}

	ret = sent_taud_emulator_clock_init();
	if (ret < 0) {
		return ret;
	}

	ret = pinctrl_apply_state(
		emulator_pinctrl,
		PINCTRL_STATE_DEFAULT);

	if (ret < 0) {
		LOG_ERR(
			"Failed to apply TAUD output pinctrl: %d",
			ret);

		return ret;
	}

	/*
	 * Ensure both channels are stopped before reconfiguration.
	 */
	R_TAUD0->TAUDnTT =
		EMU_CH_MASK;

	/*
	 * Configure the TAUD counter clock.
	 *
	 * Peripheral input clock:
	 *
	 *     40 MHz
	 *
	 * Effective TAUD counter clock:
	 *
	 *     10 MHz
	 */
	R_TAUD0->TAUDnTPS_b.TAUDnPRS3 =
		0U;

	R_TAUD0->TAUDnBRS =
		7U;

	R_TAUD0
		->TAUDnCMOR[EMU_MASTER_CH]
		.TAUDnCMOR_b.TAUDnCKS =
		3U;

	R_TAUD0
		->TAUDnCMOR[EMU_MASTER_CH]
		.TAUDnCMOR_b.TAUDnCCS =
		0U;

	R_TAUD0
		->TAUDnCMOR[EMU_SLAVE_CH]
		.TAUDnCMOR_b.TAUDnCKS =
		3U;

	R_TAUD0
		->TAUDnCMOR[EMU_SLAVE_CH]
		.TAUDnCMOR_b.TAUDnCCS =
		0U;

#if EMU_HAS_SECONDARY_SLAVE
	R_TAUD0
		->TAUDnCMOR[EMU_SECONDARY_SLAVE_CH]
		.TAUDnCMOR_b.TAUDnCKS =
		3U;

	R_TAUD0
		->TAUDnCMOR[EMU_SECONDARY_SLAVE_CH]
		.TAUDnCMOR_b.TAUDnCCS =
		0U;
#endif

	/*
	 * Configure the master as an interval timer.
	 *
	 * Software starts the master channel. Each expiration supplies the
	 * trigger used by the slave output channel.
	 */
	R_TAUD0
		->TAUDnCMOR[EMU_MASTER_CH]
		.TAUDnCMOR_b.TAUDnMAS =
		1U;

	R_TAUD0
		->TAUDnCMOR[EMU_MASTER_CH]
		.TAUDnCMOR_b.TAUDnSTS =
		0U;

	R_TAUD0
		->TAUDnCMOR[EMU_MASTER_CH]
		.TAUDnCMOR_b.TAUDnMD =
		1U;

	/*
	 * Configure the slave as the SENT waveform output.
	 *
	 * The master-channel interrupt is used as the slave start trigger.
	 * Start triggers received while operating remain valid.
	 */
	R_TAUD0
		->TAUDnCMOR[EMU_SLAVE_CH]
		.TAUDnCMOR_b.TAUDnMAS =
		0U;

	R_TAUD0
		->TAUDnCMOR[EMU_SLAVE_CH]
		.TAUDnCMOR_b.TAUDnSTS =
		4U;

	R_TAUD0
		->TAUDnCMOR[EMU_SLAVE_CH]
		.TAUDnCMOR_b.TAUDnMD =
		9U;

#if EMU_HAS_SECONDARY_SLAVE
	R_TAUD0
		->TAUDnCMOR[EMU_SECONDARY_SLAVE_CH]
		.TAUDnCMOR_b.TAUDnMAS =
		0U;

	R_TAUD0
		->TAUDnCMOR[EMU_SECONDARY_SLAVE_CH]
		.TAUDnCMOR_b.TAUDnSTS =
		4U;

	R_TAUD0
		->TAUDnCMOR[EMU_SECONDARY_SLAVE_CH]
		.TAUDnCMOR_b.TAUDnMD =
		9U;
#endif

	BUILD_ASSERT(
		EMU_SLAVE_CH == 1U,
		"Current U2x configuration expects TAUD0 channel 1");

	/*
	 * Enable TAUD0 channel 1 output.
	 *
	 * Configuration matches the reference FSP SENT emulator.
	 */
	R_TAUD0->TAUDnTOM_b.TAUDnTOM01 = 1U;
	R_TAUD0->TAUDnTOC_b.TAUDnTOC01 = 0U;
	R_TAUD0->TAUDnTOL_b.TAUDnTOL01 = 1U;
	R_TAUD0->TAUDnTO_b.TAUDnTO01 = 1U;
	R_TAUD0->TAUDnTOE_b.TAUDnTOE01 = 1U;

#if EMU_HAS_SECONDARY_SLAVE
	BUILD_ASSERT(
		EMU_SECONDARY_SLAVE_CH == 2U,
		"Current U2x secondary output expects TAUD0 channel 2");

	R_TAUD0->TAUDnTOM_b.TAUDnTOM02 = 1U;
	R_TAUD0->TAUDnTOC_b.TAUDnTOC02 = 0U;
	R_TAUD0->TAUDnTOL_b.TAUDnTOL02 = 1U;
	R_TAUD0->TAUDnTO_b.TAUDnTO02 = 1U;
	R_TAUD0->TAUDnTOE_b.TAUDnTOE02 = 1U;
#endif

	active_pulses = NULL;
	active_pulse_count = 0U;
	active_pulse_index = 0U;

	sent_taud_debug_pulse_index = 0U;
	sent_taud_debug_pulse_count = 0U;
	sent_taud_debug_current_ticks = 0U;

	k_sem_reset(&tx_done);

	IRQ_CONNECT(
		EMU_MASTER_IRQ,
		EMU_MASTER_IRQ_PRIORITY,
		sent_taud_master_isr,
		NULL,
		0);

	IRQ_CONNECT(
		EMU_SLAVE_IRQ,
		EMU_SLAVE_IRQ_PRIORITY,
		sent_taud_slave_isr,
		NULL,
		0);

	R_BSP_IrqStatusClear(
		(IRQn_Type)EMU_MASTER_IRQ);

	R_BSP_IrqStatusClear(
		(IRQn_Type)EMU_SLAVE_IRQ);

	irq_enable(EMU_MASTER_IRQ);
	irq_enable(EMU_SLAVE_IRQ);

	emulator_opened = true;

	LOG_INF(
		"TAUD SENT raw emulator opened: "
		"unit=%u master_ch=%u master_irq=%u, "
		"slave_ch=%u slave_irq=%u secondary=%u",
		EMU_TAUD_UNIT,
		EMU_MASTER_CH,
		EMU_MASTER_IRQ,
		EMU_SLAVE_CH,
		EMU_SLAVE_IRQ,
		EMU_HAS_SECONDARY_SLAVE);

	return 0;
}

int sent_taud_emulator_send_raw(
	const uint32_t *pulse_ticks,
	size_t count)
{
	int ret;

	if (!emulator_opened) {
		return -EACCES;
	}

	if ((pulse_ticks == NULL) ||
	    (count == 0U)) {
		return -EINVAL;
	}

	/*
	 * Validate the entire array before starting TAUD.
	 *
	 * This prevents an invalid later entry from being discovered only
	 * after transmission has already started.
	 */
	for (size_t i = 0U; i < count; i++) {
		uint64_t counter_value;

		if (pulse_ticks[i] == 0U) {
			return -EINVAL;
		}

		counter_value =
			(uint64_t)pulse_ticks[i] *
			(uint64_t)CONFIG_SENT_TAUD_TICK_US *
			(uint64_t)EMU_COUNTS_PER_US;

		if (counter_value >
		    ((uint64_t)UINT16_MAX + 1U)) {
			return -ERANGE;
		}
	}

	/*
	 * Stop both channels before installing the new pulse stream.
	 */
	R_TAUD0->TAUDnTT =
		EMU_CH_MASK;

	active_pulses = pulse_ticks;
	active_pulse_count = count;

	/*
	 * Pulse zero is loaded here, so the ISR begins with pulse one.
	 */
	active_pulse_index = 1U;

	sent_taud_debug_pulse_index = 0U;
	sent_taud_debug_pulse_count = count;
	sent_taud_debug_current_ticks =
		pulse_ticks[0];

	k_sem_reset(&tx_done);

	/*
	 * Load the first falling-edge-to-falling-edge period.
	 */
	R_TAUD0
		->TAUDnCDR[EMU_MASTER_CH]
		.TAUDnCDR =
		sent_taud_ticks_to_counter(
			pulse_ticks[0]);

	/*
	 * Configure the fixed low-level pulse duration on the output
	 * channel, matching the original FSP emulator.
	 */
	R_TAUD0
		->TAUDnCDR[EMU_SLAVE_CH]
		.TAUDnCDR =
		sent_taud_ticks_to_counter(
			EMU_LOW_TICKS);


#if EMU_HAS_SECONDARY_SLAVE
	R_TAUD0
		->TAUDnCDR[EMU_SECONDARY_SLAVE_CH]
		.TAUDnCDR =
		sent_taud_ticks_to_counter(
			EMU_LOW_TICKS);
#endif

	R_BSP_IrqStatusClear(
		(IRQn_Type)EMU_MASTER_IRQ);

	R_BSP_IrqStatusClear(
		(IRQn_Type)EMU_SLAVE_IRQ);

	/*
	 * Simultaneously start master and slave.
	 */
	R_TAUD0->TAUDnTS =
		EMU_CH_MASK;

	ret = k_sem_take(
		&tx_done,
		K_MSEC(
			CONFIG_SENT_TAUD_TX_TIMEOUT_MS));

	if (ret != 0) {
		R_TAUD0->TAUDnTT =
			EMU_CH_MASK;

		/*
		 * Prevent either TAUD ISR from observing cleared transmission
		 * state while recovering from a timeout.
		 */
		irq_disable(EMU_MASTER_IRQ);
		irq_disable(EMU_SLAVE_IRQ);

		R_BSP_IrqStatusClear(
			(IRQn_Type)EMU_MASTER_IRQ);

		R_BSP_IrqStatusClear(
			(IRQn_Type)EMU_SLAVE_IRQ);

		active_pulses = NULL;
		active_pulse_count = 0U;
		active_pulse_index = 0U;

		irq_enable(EMU_MASTER_IRQ);
		irq_enable(EMU_SLAVE_IRQ);

		LOG_ERR(
			"TAUD raw transmission timeout: "
			"pulse_index=%u pulse_count=%u "
			"current_ticks=%u",
			(uint32_t)
				sent_taud_debug_pulse_index,
			(uint32_t)
				sent_taud_debug_pulse_count,
			sent_taud_debug_current_ticks);

		return -ETIMEDOUT;
	}

	active_pulses = NULL;
	active_pulse_count = 0U;
	active_pulse_index = 0U;

	return 0;
}

int sent_taud_emulator_close(void)
{
	if (!emulator_opened) {
		return 0;
	}

	irq_disable(EMU_MASTER_IRQ);
	irq_disable(EMU_SLAVE_IRQ);

	R_TAUD0->TAUDnTT =
		EMU_CH_MASK;

	R_BSP_IrqStatusClear(
		(IRQn_Type)EMU_MASTER_IRQ);

	R_BSP_IrqStatusClear(
		(IRQn_Type)EMU_SLAVE_IRQ);

	R_TAUD0->TAUDnTOE_b.TAUDnTOE01 = 0U;
	R_TAUD0->TAUDnTO_b.TAUDnTO01 = 0U;
	R_TAUD0->TAUDnTOL_b.TAUDnTOL01 = 0U;
	R_TAUD0->TAUDnTOC_b.TAUDnTOC01 = 0U;
	R_TAUD0->TAUDnTOM_b.TAUDnTOM01 = 0U;

#if EMU_HAS_SECONDARY_SLAVE
	R_TAUD0->TAUDnTOE_b.TAUDnTOE02 = 0U;
	R_TAUD0->TAUDnTO_b.TAUDnTO02 = 0U;
	R_TAUD0->TAUDnTOL_b.TAUDnTOL02 = 0U;
	R_TAUD0->TAUDnTOC_b.TAUDnTOC02 = 0U;
	R_TAUD0->TAUDnTOM_b.TAUDnTOM02 = 0U;
#endif

	active_pulses = NULL;
	active_pulse_count = 0U;
	active_pulse_index = 0U;

	emulator_opened = false;

	k_sem_reset(&tx_done);

	LOG_INF(
		"TAUD SENT raw emulator closed");

	return 0;
}
```

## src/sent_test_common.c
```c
/*
 * Copyright (c) 2026 Renesas Electronics Corporation
 * SPDX-License-Identifier: Apache-2.0
 */

#include "sent_test_common.h"

#include <errno.h>
#include <string.h>

void sent_test_rx_context_reset(struct sent_test_rx_context *ctx)
{
	memset(ctx->frames, 0, sizeof(ctx->frames));
	ctx->callback_count = 0U;
	ctx->frame_total = 0U;
	k_sem_reset(&ctx->done);
}

void sent_test_fast_cb(const struct device *dev, uint8_t channel,
					   uint32_t num_frame, void *user_data)
{
	struct sent_test_rx_context *ctx = user_data;

	ARG_UNUSED(dev);

	if ((channel != SENT_TEST_CHANNEL) || (num_frame == 0U) || (ctx == NULL)) {
		return;
	}

	ctx->callback_count++;
	ctx->frame_total += num_frame;

	/*
	 * For multichannel operation, user_data points to the matching
	 * multi_rx[i] context, so this releases that receiver's own waiter.
	 */
	k_sem_give(&ctx->done);
}

int sent_test_rx_context_init(struct sent_test_rx_context *ctx)
{
	int ret;

	memset(ctx, 0, sizeof(*ctx));

	ret = k_sem_init(&ctx->done, 0U, 1U);
	if (ret != 0) {
		return ret;
	}

	ctx->fast_config.callback = sent_test_fast_cb;
	ctx->fast_config.frame = ctx->frames;
	ctx->fast_config.max_num_frame = ARRAY_SIZE(ctx->frames);
	ctx->fast_config.user_data = ctx;
	ctx->callback_configs.fast = &ctx->fast_config;
	ctx->callback_configs.serial = NULL;

	return 0;
}

int sent_test_start_fast(const struct device *dev,
						 struct sent_test_rx_context *ctx,
						 uint32_t batch_size)
{
	int ret;

	if ((batch_size == 0U) || (batch_size > ARRAY_SIZE(ctx->frames))) {
		return -EINVAL;
	}

	ctx->fast_config.max_num_frame = batch_size;

	ret = sent_register_callback(dev, SENT_TEST_CHANNEL,
								 ctx->callback_configs);
	if (ret != 0) {
		return ret;
	}

	ret = sent_start_listening(dev, SENT_TEST_CHANNEL);
	if (ret == 0) {
		k_msleep(10U);
	}

	return ret;
}

int sent_test_stop(const struct device *dev)
{
	int ret = sent_stop_listening(dev, SENT_TEST_CHANNEL);

	return (ret == -EALREADY) ? 0 : ret;
}
```

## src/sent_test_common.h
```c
/*
 * Copyright (c) 2026 Renesas Electronics Corporation
 * SPDX-License-Identifier: Apache-2.0
 */

#ifndef SENT_TEST_COMMON_H_
#define SENT_TEST_COMMON_H_

#include <stdint.h>

#include <zephyr/device.h>
#include <zephyr/drivers/sent/sent.h>
#include <zephyr/kernel.h>

#define SENT_TEST_CHANNEL	0U
#define SENT_TEST_MAX_FRAMES 100U

struct sent_test_rx_context {
	struct sent_frame frames[SENT_TEST_MAX_FRAMES];

	struct k_sem done;

	volatile uint32_t callback_count;
	volatile uint32_t frame_total;

	/*
	 * These objects must remain valid after sent_test_start_fast()
	 * returns. Keep them in the persistent receive context instead of
	 * declaring them as local stack variables.
	 */
	struct sent_rx_callback_config fast_config;
	struct sent_rx_callback_configs callback_configs;
};

int sent_test_rx_context_init(
	struct sent_test_rx_context *ctx);

void sent_test_rx_context_reset(
	struct sent_test_rx_context *ctx);

void sent_test_fast_cb(
	const struct device *dev,
	uint8_t channel,
	uint32_t num_frame,
	void *user_data);

int sent_test_start_fast(
	const struct device *dev,
	struct sent_test_rx_context *ctx,
	uint32_t batch_size);

int sent_test_stop(
	const struct device *dev);

#endif /* SENT_TEST_COMMON_H_ */
```

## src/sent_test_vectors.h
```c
/*
 * Copyright (c) 2026 Renesas Electronics Corporation
 * SPDX-License-Identifier: Apache-2.0
 */

#ifndef SENT_TEST_VECTORS_H_
#define SENT_TEST_VECTORS_H_

#include <stdint.h>

#include <zephyr/sys/util.h>

/*
 * SENT raw-period encoding used by every vector below
 * ===================================================
 *
 * The emulator array contains falling-edge-to-falling-edge periods in SENT
 * ticks. It does not contain high time or low time separately.
 *
 * Calibration pulse:
 *
 *	 period = 56 ticks
 *
 * Status, data and CRC nibbles:
 *
 *	 period_ticks = 12 + nibble_value
 *
 * Examples:
 *
 *	 nibble 0x0 -> 12 + 0  = 12 ticks
 *	 nibble 0x1 -> 12 + 1  = 13 ticks
 *	 nibble 0x5 -> 12 + 5  = 17 ticks
 *	 nibble 0xF -> 12 + 15 = 27 ticks
 *
 * Each ordinary frame in this test has:
 *
 *	 [calibration]
 *	 [status]
 *	 [data0] [data1] [data2] [data3] [data4] [data5]
 *	 [CRC]
 *
 * Therefore one frame has 9 raw period entries.
 */

/*
 * Known-good FSP reference vector
 * ===============================
 */
static const uint32_t fsp_enhanced_serial_format_0_pulses[] = {
	/*
	 * Dummy frame
	 */
	56U, 12U, 12U, 12U, 12U, 12U, 12U, 12U, 17U,

	56U, 23U, 12U, 12U, 12U, 12U, 12U, 12U, 17U,
	56U, 23U, 12U, 12U, 12U, 12U, 12U, 13U, 17U,
	56U, 23U, 12U, 12U, 12U, 12U, 12U, 14U, 17U,
	56U, 23U, 12U, 12U, 12U, 12U, 12U, 15U, 17U,
	56U, 23U, 12U, 12U, 12U, 12U, 12U, 16U, 17U,
	56U, 23U, 12U, 12U, 12U, 12U, 12U, 17U, 17U,
	56U, 19U, 12U, 12U, 12U, 12U, 12U, 18U, 17U,
	56U, 19U, 12U, 12U, 12U, 12U, 12U, 19U, 17U,
	56U, 23U, 12U, 12U, 12U, 12U, 12U, 20U, 17U,
	56U, 19U, 12U, 12U, 12U, 12U, 12U, 21U, 17U,
	56U, 27U, 12U, 12U, 12U, 12U, 12U, 22U, 17U,
	56U, 27U, 12U, 12U, 12U, 12U, 12U, 23U, 17U,
	56U, 19U, 12U, 12U, 12U, 12U, 12U, 24U, 17U,
	56U, 23U, 12U, 12U, 12U, 12U, 12U, 25U, 17U,
	56U, 27U, 12U, 12U, 12U, 12U, 12U, 26U, 17U,
	56U, 19U, 12U, 12U, 12U, 12U, 12U, 27U, 17U,
	56U, 19U, 12U, 12U, 12U, 12U, 13U, 12U, 17U,
	56U, 19U, 12U, 12U, 12U, 12U, 13U, 13U, 17U,

	/* Stream termination / following calibration periods. */
	56U,
	56U,
};

static const uint8_t expected_final_nibble[19] = {
	/* dummy */
	0x0,

	/* ES 1..18 */
	0x0, 0x1, 0x2, 0x3,
	0x4, 0x5, 0x6, 0x7,
	0x8, 0x9, 0xA, 0xB,
	0xC, 0xD, 0xE, 0xF,
	0x0, 0x1,
};

static const uint8_t expected_nibble4[19] = {
	/* dummy */
	0x0,

	/* ES 1..16 */
	0x0, 0x0, 0x0, 0x0,
	0x0, 0x0, 0x0, 0x0,
	0x0, 0x0, 0x0, 0x0,
	0x0, 0x0, 0x0, 0x0,

	/* ES 17..18 */
	0x1, 0x1,
};

#define FSP_REFERENCE_FRAME_COUNT 19U
#define FSP_REFERENCE_PERIODS_PER_FRAME 9U
#define FSP_REFERENCE_TERMINATION_COUNT 2U

BUILD_ASSERT(
	ARRAY_SIZE(fsp_enhanced_serial_format_0_pulses) ==
		((FSP_REFERENCE_FRAME_COUNT * FSP_REFERENCE_PERIODS_PER_FRAME) +
		 FSP_REFERENCE_TERMINATION_COUNT),
	"Unexpected FSP reference-vector length");

/*
 * Known-good single frame
 * =======================
 *
 * This is the first/dummy frame from the known-good FSP vector, followed by
 * two calibration periods:
 *
 *	 status = 0x0
 *	 data   = {0, 0, 0, 0, 0, 0}
 *	 CRC raw field = 0x5
 *
 * Raw conversion:
 *
 *	 0x0 -> 12 ticks
 *	 0x5 -> 17 ticks
 */
static const uint32_t known_good_single_frame[] = {
	56U,
	12U,
	12U, 12U, 12U, 12U, 12U, 12U,
	17U,
	56U,
	56U,
};

/*
 * Calibration-error frame
 * =======================
 *
 * Identical to known_good_single_frame except calibration is deliberately
 * changed from 56 ticks to 30 ticks. The receiver should reject this frame.
 */
static const uint32_t bad_calibration_single_frame[] = {
	30U,
	12U,
	12U, 12U, 12U, 12U, 12U, 12U,
	17U,
	56U,
	56U,
};

/*
 * Explicit CRC vectors
 * ====================
 *
 * Payload used for CRC validation:
 *
 *	 status = 0x0
 *	 data   = {0x1, 0x2, 0x3, 0x4, 0x5, 0x6}
 *
 * Data periods:
 *
 *	 0x1 -> 13
 *	 0x2 -> 14
 *	 0x3 -> 15
 *	 0x4 -> 16
 *	 0x5 -> 17
 *	 0x6 -> 18
 *
 * CRC calculation recorded here for later validation:
 *
 *	 polynomial = x^4 + x^3 + x^2 + 1 = 0x0D
 *	 seed	   = 0x05
 *
 */
static const uint32_t recommended_crc_single_frame[] = {
	56U,
	12U,
	13U, 14U, 15U, 16U, 17U, 18U,
	14U,
	56U,
	56U,
};

static const uint32_t legacy_crc_single_frame[] = {
	56U,
	12U,
	13U, 14U, 15U, 16U, 17U, 18U,
	25U,
	56U,
	56U,
};

/*
 * Corrupted CRC candidates
 * ========================
 *
 * Only the CRC period is changed. The corruption uses CRC nibble XOR 0x1:
 *
 *	 recommended: 0x1 XOR 0x1 = 0x0 -> 12 ticks
 *	 legacy:	  0x8 XOR 0x1 = 0x9 -> 21 ticks
 */
static const uint32_t bad_recommended_crc_single_frame[] = {
	56U,
	12U,
	13U, 14U, 15U, 16U, 17U, 18U,
	12U,
	56U,
	56U,
};

static const uint32_t bad_legacy_crc_single_frame[] = {
	56U,
	12U,
	13U, 14U, 15U, 16U, 17U, 18U,
	21U,
	56U,
	56U,
};

/*
 * Variable pause-pulse vector
 * ===========================
 *
 * Four known-good zero-data frames are followed by explicit pause periods.
 * The pause is inserted after the CRC period and before the next calibration
 * period. The four pause periods are intentionally different:
 *
 *	 frame 0 pause = 32 ticks
 *	 frame 1 pause = 40 ticks
 *	 frame 2 pause = 48 ticks
 *	 frame 3 pause = 64 ticks
 *
 * Frame layout with pause:
 *
 *	 56, status, data0..data5, CRC, pause
 */
static const uint32_t variable_pause_frames[] = {
	56U, 12U, 12U, 12U, 12U, 12U, 12U, 12U, 17U, 32U,
	56U, 12U, 12U, 12U, 12U, 12U, 12U, 12U, 17U, 40U,
	56U, 12U, 12U, 12U, 12U, 12U, 12U, 12U, 17U, 48U,
	56U, 12U, 12U, 12U, 12U, 12U, 12U, 12U, 17U, 64U,
	56U,
	56U,
};

/*
 * Fixed pause-pulse vector
 * ========================
 *
 * Same safe zero-data frame repeated four times. Every frame uses the same
 * explicit 64-tick pause period.
 */
static const uint32_t fixed_pause_frames[] = {
	56U, 12U, 12U, 12U, 12U, 12U, 12U, 12U, 17U, 64U,
	56U, 12U, 12U, 12U, 12U, 12U, 12U, 12U, 17U, 64U,
	56U, 12U, 12U, 12U, 12U, 12U, 12U, 12U, 17U, 64U,
	56U, 12U, 12U, 12U, 12U, 12U, 12U, 12U, 17U, 64U,
	56U,
	56U,
};

#endif /* SENT_TEST_VECTORS_H_ */
```
